# RA4M1 register map
Vendor: Renesas Electronics Corporation; Series: RA4; File version: 1.2
CPU: CM4 r0p1, little endian, MPU, FPU, VTOR, 4 interrupt priority bits
Registers are 8-bit, read-write, reset 0x0 unless marked. A register's access mark holds for its fields unless they carry their own. Offsets are from the block's base; [hi:lo] are bit positions.

## AGT0 — Asynchronous General purpose Timer 0
Base 0x40084000
Same registers: AGT1 0x40084100
0x00 AGT 16-bit reset 0xFFFF — AGT Counter Register
  [15:0] AGT — 16bit counter and reload register NOTE : When 1 is written to the TSTOP bit in the AGTCRn register, the 16-bit counter is forcibly stopped and set to FFFFH.
0x02 AGTCMA 16-bit reset 0xFFFF — AGT Compare Match A Register
  [15:0] AGTCMA — AGT Compare Match A data is stored. NOTE : When 1 is written to the TSTOP bit in the AGTCRn register, set to FFFFH
0x04 AGTCMB 16-bit reset 0xFFFF — AGT Compare Match B Register
  [15:0] AGTCMB — AGT Compare Match B data is stored. NOTE : When 1 is written to the TSTOP bit in the AGTCR register, set to FFFFH
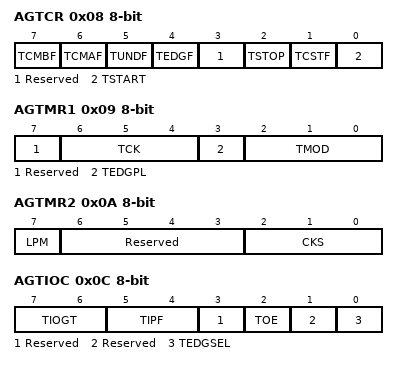
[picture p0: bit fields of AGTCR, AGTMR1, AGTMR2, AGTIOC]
0x08 AGTCR — AGT Control Register
  [7] TCMBF write-0-clears read-modifies — Compare match B flag
    0=No match; 1=Match
  [6] TCMAF write-0-clears read-modifies — Compare match A flag
    0=No match; 1=Match
  [5] TUNDF write-0-clears read-modifies — Underflow flag
    0=No match; 1=Match
  [4] TEDGF write-0-clears read-modifies — Active edge judgment flag
    0=No active edge received; 1=Active edge received
  [3] Reserved — This bit is read as 0. The write value should be 0.
  [2] TSTOP wo — AGT count forced stop
    0=Writing is invalid; 1=The count is forcibly stopped
  [1] TCSTF ro — AGT count status flag
    0=Count stops; 1=Count in progress
  [0] TSTART — AGT count start
    0=Count stops; 1=Count starts
0x09 AGTMR1 — AGT Mode Register 1
  [7] Reserved — This bit is read as 0. The write value should be 0.
  [6:4] TCK — Count source
    0=PCLKB; 1=PCLKB/8; 3=PCLKB/2; 4=Divided clock AGTLCLK specified by CKS[2:0] bits in the AGTMR2 register; 5=Underflow event signal from AGT0*6; 6=Divided clock AGTSCLK specified by CKS[2:0] bits in the AGTMR2 register; other=others (settings are prohibited.)
  [3] TEDGPL — Edge polarity
    0=Single-edge; 1=Both-edge
  [2:0] TMOD — Operating mode
    0=Timer mode; 1=Pulse output mode; 2=Event counter mode; 3=Pulse width measurement mode; 4=Pulse period measurement mode; other=others (settings are prohibited)
0x0A AGTMR2 — AGT Mode Register 2
  [7] LPM — Low Power Mode
    0=Normal mode; 1=Low Power mode
  [6:3] Reserved — These bits are read as 0000. The write value should be 0000.
  [2:0] CKS — AGTLCLK/AGTSCLK count source clock frequency division ratio
    0=1/1; 1=1/2; 2=1/4; 3=1/8; 4=1/16; 5=1/32; 6=1/64; 7=1/128
0x0C AGTIOC — AGT I/O Control Register
  [7:6] TIOGT — Count control
    0=Event is always counted; 1=Event is counted during polarity period specified for AGTEEn; other=others (settings are prohibited.)
  [5:4] TIPF — Input filter
    0=No filter; 1=Filter sampled at PCLKB; 2=Filter sampled at PCLKB/8; 3=Filter sampled at PCLKB/32
  [3] Reserved — This bit is read as 0. The write value should be 0.
  [2] TOE — AGTOn output enable
    0=AGTOn output disabled; 1=AGTOn output enabled
  [1] Reserved — This bit is read as 0. The write value should be 0.
  [0] TEDGSEL — I/O polarity switch Function varies depending on the operating mode.
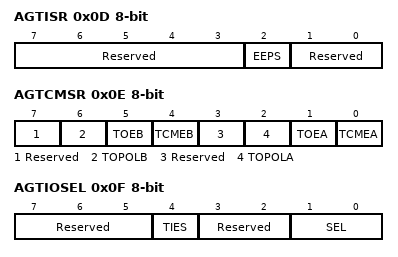
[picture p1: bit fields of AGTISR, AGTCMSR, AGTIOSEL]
0x0D AGTISR — AGT Event Pin Select Register
  [7:3] Reserved — These bits are read as 00000. The write value should be 00000.
  [2] EEPS — AGTEE polarty selection
    0=An event is counted during the low-level period; 1=An event is counted during the high-level period
  [1:0] Reserved — These bits are read as 00. The write value should be 00.
0x0E AGTCMSR — AGT Compare Match Function Select Register
  [7] Reserved — This bit is read as 0. The write value should be 0.
  [6] TOPOLB — AGTOB polarity select
    0=AGTOB Output is started at low; 1=AGTOB Output is started at high
  [5] TOEB — AGTOB output enable
    0=AGTOB output disabled (port); 1=AGTOB output enabled
  [4] TCMEB — Compare match B register enable
    0=Disable compare match B register; 1=Enable compare match B register
  [3] Reserved — This bit is read as 0. The write value should be 0.
  [2] TOPOLA — AGTOA polarity select
    0=AGTOA Output is started at low; 1=AGTOA Output is started at high
  [1] TOEA — AGTOA output enable
    0=AGTOA output disabled (port); 1=AGTOA output enabled
  [0] TCMEA — Compare match A register enable
    0=Disable compare match A register; 1=Enable compare match A register
0x0F AGTIOSEL — AGT Pin Select Register
  [7:5] Reserved — These bits are read as 000. The write value should be 000.
  [4] TIES — AGTIO input enable
    0=External event input is disabled during Software Standby mode; 1=External event input is enabled during Software Standby mode
  [3:2] Reserved — These bits are read as 00. The write value should be 00.
  [1:0] SEL — AGTIO pin select
    0=Select the AGTIOn except for below pins; 1=Setting prohibited; 2=Select the P402/AGTIOn. P402/AGTIOn is input only. It is not possible to output; 3=Select the P403/AGTIOn. P403/AGTIOn is input only. It is not possible to output
